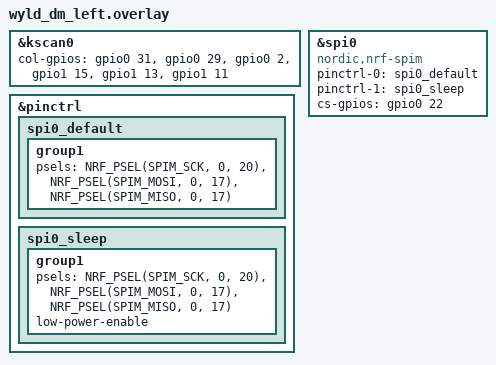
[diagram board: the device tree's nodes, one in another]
// wyld_dm_left.overlay

#include "wyld_dm.dtsi"
#include <dt-bindings/led/led.h>

///  NANO V2 PINS

&kscan0 {
    col-gpios
			= <&gpio0 31  GPIO_ACTIVE_HIGH>  // 0.31
			, <&gpio0 29  GPIO_ACTIVE_HIGH>  // 0.29
            , <&gpio0 2  GPIO_ACTIVE_HIGH>  // 0.02
			, <&gpio1 15  GPIO_ACTIVE_HIGH>  //  1.15
			, <&gpio1 13  GPIO_ACTIVE_HIGH>  // 1.13
			, <&gpio1 11  GPIO_ACTIVE_HIGH>  //  1.11
//            , <&gpio1 04 GPIO_ACTIVE_HIGH>  // PB13   / 1.04
			;
};

&pinctrl {
    spi0_default: spi0_default {
        group1 {
            psels = <NRF_PSEL(SPIM_SCK, 0, 20)>,
                <NRF_PSEL(SPIM_MOSI, 0, 17)>,
			    <NRF_PSEL(SPIM_MISO, 0, 17)>;
        };
    };
    spi0_sleep: spi0_sleep {
        group1 {
            psels = <NRF_PSEL(SPIM_SCK, 0, 20)>,
                <NRF_PSEL(SPIM_MOSI, 0, 17)>,
			    <NRF_PSEL(SPIM_MISO, 0, 17)>;
            low-power-enable;
        };
    };
};

nice_view_spi: &spi0 {
    compatible = "nordic,nrf-spim";
    pinctrl-0 = <&spi0_default>;
    pinctrl-1 = <&spi0_sleep>;
    pinctrl-names = "default", "sleep";
    cs-gpios = <&gpio0 22 GPIO_ACTIVE_HIGH>;
};





